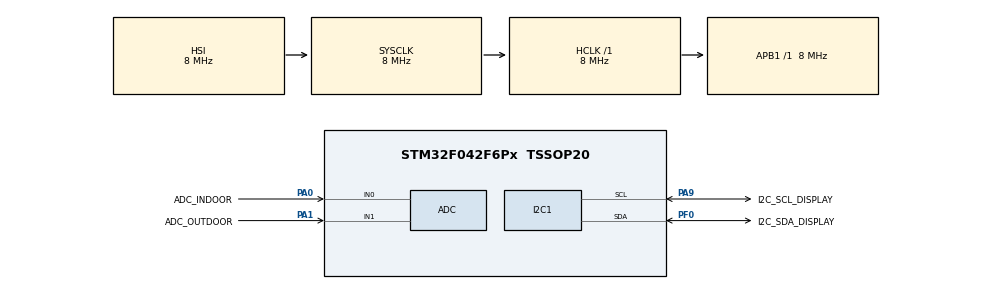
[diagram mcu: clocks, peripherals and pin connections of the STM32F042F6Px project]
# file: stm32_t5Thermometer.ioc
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ADC.ContinuousConvMode=ENABLE
ADC.DMAContinuousRequests=ENABLE
ADC.EOCSelection=ADC_EOC_SEQ_CONV
ADC.SamplingTime=ADC_SAMPLETIME_239CYCLES_5
Dma.ADC.0.Direction=DMA_PERIPH_TO_MEMORY
Dma.ADC.0.Instance=DMA1_Channel1
Dma.ADC.0.MemDataAlignment=DMA_MDATAALIGN_WORD
Dma.ADC.0.MemInc=DMA_MINC_ENABLE
Dma.ADC.0.Mode=DMA_NORMAL
Dma.ADC.0.PeriphDataAlignment=DMA_PDATAALIGN_WORD
Dma.ADC.0.PeriphInc=DMA_PINC_DISABLE
Dma.ADC.0.Priority=DMA_PRIORITY_LOW
Dma.Request0=ADC
I2C1.Timing=0x00201D2B
Mcu.Family=STM32F0
Mcu.Name=STM32F042F6Px
Mcu.Package=TSSOP20
NVIC.DMA1_Channel1_IRQn=true\:0\:0\:false\:false\:true\:false\:true\:true
PA0.GPIO_Label=ADC_INDOOR
PA0.Mode=IN0
PA0.Signal=ADC_IN0
PA1.GPIO_Label=ADC_OUTDOOR
PA1.Mode=IN1
PA1.Signal=ADC_IN1
PA13.Mode=Serial_Wire
PA13.Signal=SYS_SWDIO
PA14.Mode=Serial_Wire
PA14.Signal=SYS_SWCLK
PA2.GPIO_Label=USART2_TX_DBG
PA2.Signal=USART2_TX
PA9.GPIO_Label=I2C_SCL_DISPLAY
PA9.GPIO_Pu=GPIO_PULLUP
PA9.Mode=I2C
PA9.Signal=I2C1_SCL
PF0-OSC_IN.GPIO_Label=I2C_SDA_DISPLAY
PF0-OSC_IN.GPIO_Pu=GPIO_PULLUP
PF0-OSC_IN.Mode=I2C
PF0-OSC_IN.Signal=I2C1_SDA
ProjectManager.HeapSize=0x200
ProjectManager.StackSize=0x400
ProjectManager.TargetToolchain=Makefile
RCC.AHBFreq_Value=8000000
RCC.APB1Freq_Value=8000000
RCC.APB1TimFreq_Value=8000000
RCC.HCLKFreq_Value=8000000
RCC.I2c1ClockSelection=RCC_I2C1CLKSOURCE_SYSCLK
RCC.SYSCLKFreq_VALUE=8000000
board=custom

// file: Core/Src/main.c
/* USER CODE BEGIN Header */
/**
  ******************************************************************************
  * @file           : main.c
  * @brief          : Main program body
  ******************************************************************************
  * @attention
  *
  * Copyright (c) 2024 STMicroelectronics.
  * All rights reserved.
  *
  * This software is licensed under terms that can be found in the LICENSE file
  * in the root directory of this software component.
  * If no LICENSE file comes with this software, it is provided AS-IS.
  *
  ******************************************************************************
  */
/* USER CODE END Header */
#include "main.h"
#include "adc.h"
#include "dma.h"
#include "i2c.h"
#include "gpio.h"

/* USER CODE BEGIN Includes */

#include "prj_main.h"
/* USER CODE END Includes */

void SystemClock_Config(void);

int main(void)
{

  /* MCU Configuration--------------------------------------------------------*/

  /* Reset of all peripherals, Initializes the Flash interface and the Systick. */
  HAL_Init();

  /* Configure the system clock */
  SystemClock_Config();

  /* Initialize all configured peripherals */
  MX_GPIO_Init();
  MX_DMA_Init();
  MX_I2C1_Init();
  MX_ADC_Init();
  /* USER CODE BEGIN 2 */
  prj_main();
  /* USER CODE END 2 */

  /* Infinite loop */
  while (1)
  {

  }
}

void SystemClock_Config(void)
{
  RCC_OscInitTypeDef RCC_OscInitStruct = {0};
  RCC_ClkInitTypeDef RCC_ClkInitStruct = {0};
  RCC_PeriphCLKInitTypeDef PeriphClkInit = {0};

  /** Initializes the RCC Oscillators according to the specified parameters
  * in the RCC_OscInitTypeDef structure.
  */
  RCC_OscInitStruct.OscillatorType = RCC_OSCILLATORTYPE_HSI|RCC_OSCILLATORTYPE_HSI14;
  RCC_OscInitStruct.HSIState = RCC_HSI_ON;
  RCC_OscInitStruct.HSI14State = RCC_HSI14_ON;
  RCC_OscInitStruct.HSICalibrationValue = RCC_HSICALIBRATION_DEFAULT;
  RCC_OscInitStruct.HSI14CalibrationValue = 16;
  RCC_OscInitStruct.PLL.PLLState = RCC_PLL_NONE;
  if (HAL_RCC_OscConfig(&RCC_OscInitStruct) != HAL_OK)
  {
    Error_Handler();
  }

  /** Initializes the CPU, AHB and APB buses clocks
  */
  RCC_ClkInitStruct.ClockType = RCC_CLOCKTYPE_HCLK|RCC_CLOCKTYPE_SYSCLK
                              |RCC_CLOCKTYPE_PCLK1;
  RCC_ClkInitStruct.SYSCLKSource = RCC_SYSCLKSOURCE_HSI;
  RCC_ClkInitStruct.AHBCLKDivider = RCC_SYSCLK_DIV1;
  RCC_ClkInitStruct.APB1CLKDivider = RCC_HCLK_DIV1;

  if (HAL_RCC_ClockConfig(&RCC_ClkInitStruct, FLASH_LATENCY_0) != HAL_OK)
  {
    Error_Handler();
  }
  PeriphClkInit.PeriphClockSelection = RCC_PERIPHCLK_I2C1;
  PeriphClkInit.I2c1ClockSelection = RCC_I2C1CLKSOURCE_SYSCLK;
  if (HAL_RCCEx_PeriphCLKConfig(&PeriphClkInit) != HAL_OK)
  {
    Error_Handler();
  }
}

void Error_Handler(void)
{
  /* USER CODE BEGIN Error_Handler_Debug */
  /* User can add his own implementation to report the HAL error return state */
  __disable_irq();
  while (1)
  {
    //HAL_UART_Transmit(&huart1, (uint8_t*)"Error!\r\n", 7, HAL_MAX_DELAY);
    HAL_Delay(100);
  }
  /* USER CODE END Error_Handler_Debug */
}
